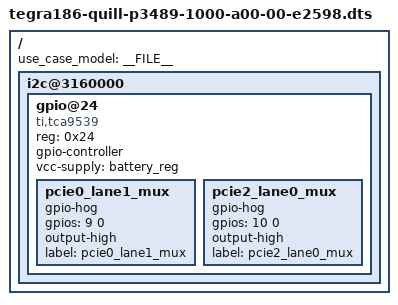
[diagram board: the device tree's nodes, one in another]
/*
 * tegra186-quill-p3489-a00-00-e2598.dts Storm A00 Board
 *
 * Copyright (c) 2018, NVIDIA CORPORATION. All rights reserved.
 *
 * This program is free software; you can redistribute it and/or modify
 * it under the terms of the GNU General Public License as published by
 * the Free Software Foundation; version 2 of the License.
 *
 * This program is distributed in the hope that it will be useful, but WITHOUT
 * ANY WARRANTY; without even the implied warranty of MERCHANTABILITY or
 * FITNESS FOR A PARTICULAR PURPOSE.  See the GNU General Public License for
 * more details.
 */

#include "tegra186-quill-p3489-1000-a00-00-base.dts"

/ {
	use_case_model = __FILE__;

	i2c@3160000 {
		gpio@24 {
			compatible = "ti,tca9539";
			reg = <0x24>;
			gpio-controller;
			#gpio-cells = <2>;
			vcc-supply = <&battery_reg>;
			pcie0_lane1_mux {
				gpio-hog;
				gpios = <9 0>;
				output-high;
				label = "pcie0_lane1_mux";
				status = "okay";
			};
			pcie2_lane0_mux {
				gpio-hog;
				gpios = <10 0>;
				output-high;
				label = "pcie2_lane0_mux";
				status = "okay";
			};
		};
	};
};
